# STM32U5A9xx register map
File version: 1.0
Registers are 32-bit, read-write, reset 0x0 unless marked. A register's access mark holds for its fields unless they carry their own. Offsets are from the block's base; [hi:lo] are bit positions; 'fields as' and 'values as' point back to an identical list.

## OCTOSPI1 — HEXA and OCTO Serial Peripheral Interface
Base 0x420D1400
Same registers: OCTOSPI2 0x420D2400, OCTOSPI1_S 0x520D1400, OCTOSPI2_S 0x520D2400
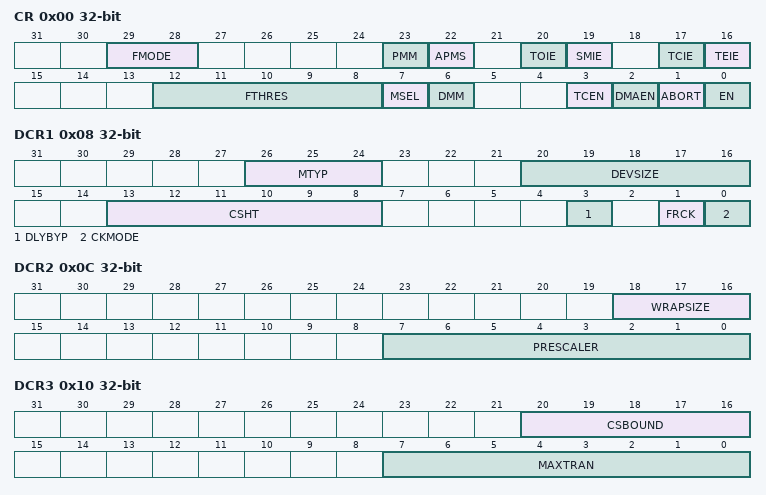
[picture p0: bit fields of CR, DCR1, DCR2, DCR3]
0x00 CR — XSPI Control register
  [29:28] FMODE — Functional Mode
  [23] PMM — Polling Match Mode
  [22] APMS — Automatic Poll Mode Stop
  [20] TOIE — TimeOut Interrupt Enable
  [19] SMIE — Status Match Interrupt Enable
  [17] TCIE — Transfer Complete Interrupt Enable
  [16] TEIE — Transfer Error Interrupt Enable
  [12:8] FTHRES — FIFO Threshold Level
  [7] MSEL — Memory Select
  [6] DMM — Dual Memory Mode
  [3] TCEN — Timeout Counter Enable
  [2] DMAEN — DMA Enable
  [1] ABORT — Abort request
  [0] EN — Enable
0x08 DCR1 — XSPI Device Configuration register 1
  [26:24] MTYP — Memory Type
  [20:16] DEVSIZE — Device Size
  [13:8] CSHT — Chip Select High Time
  [3] DLYBYP — Delay Block Bypass
  [1] FRCK — Free Running Clock
  [0] CKMODE — Mode 0 / Mode 3
0x0C DCR2 — XSPI Device Configuration register 2
  [18:16] WRAPSIZE
  [7:0] PRESCALER — Clock prescaler
0x10 DCR3 — XSPI Device Configuration register 3
  [20:16] CSBOUND — Maximum transfer
  [7:0] MAXTRAN — Maximum transfer
0x14 DCR4 — XSPI Device Configuration register 4
  [31:0] REFRESH — Refresh rate
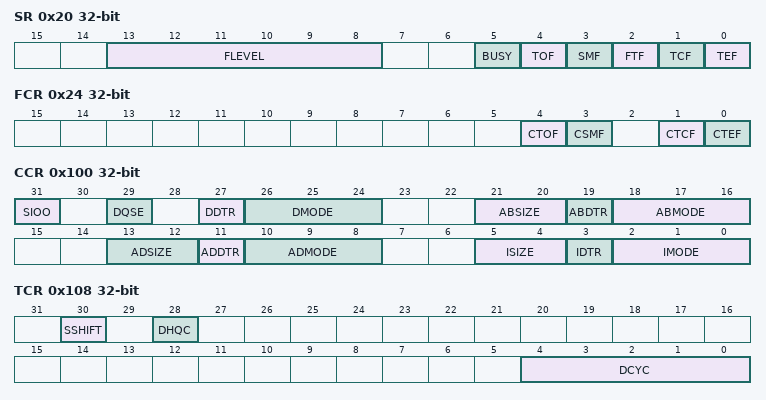
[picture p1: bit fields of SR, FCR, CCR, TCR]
0x20 SR — XSPI Status register
  [13:8] FLEVEL — FIFO Level
  [5] BUSY
  [4] TOF — Timeout Flag
  [3] SMF — Status Match Flag
  [2] FTF — FIFO Threshold Flag
  [1] TCF — Transfer Complete Flag
  [0] TEF — Transfer Error Flag
0x24 FCR — XSPI Flag Clear register
  [4] CTOF — Clear Timeout Flag
  [3] CSMF — Clear Status Match Flag
  [1] CTCF — Clear Transfer Complete Flag
  [0] CTEF — Clear Transfer Error Flag
0x40 DLR — XSPI Data Length register
  [31:0] DL — Data Length
0x48 AR — XSPI Address register
  [31:0] ADDRESS
0x50 DR — XSPI Data register
  [31:0] DATA
0x80 PSMKR — XSPI Polling Status Mask register
  [31:0] MASK — Status mask
0x88 PSMAR — XSPI Polling Status Match register
  [31:0] MATCH — Status match
0x90 PIR — XSPI Polling Interval register
  [15:0] INTERVAL — Polling Interval
0x100 CCR — XSPI Communication Configuration register
  [31] SIOO — Send Instruction Only Once Mode
  [29] DQSE — DQS Enable
  [27] DDTR — Data Double Transfer Rate
  [26:24] DMODE — Data Mode
  [21:20] ABSIZE — Alternate Bytes Size
  [19] ABDTR — Alternate Bytes Double Transfer Rate
  [18:16] ABMODE — Alternate Bytes Mode
  [13:12] ADSIZE — Address Size
  [11] ADDTR — Address Double Transfer Rate
  [10:8] ADMODE — Address Mode
  [5:4] ISIZE — Instruction Size
  [3] IDTR — Instruction Double Transfer Rate
  [2:0] IMODE — Instruction Mode
0x108 TCR — XSPI Timing Configuration register
  [30] SSHIFT — Sample Shift
  [28] DHQC — Delay Hold Quarter Cycle
  [4:0] DCYC — Number of Dummy Cycles
0x110 IR — XSPI Instruction register
  [31:0] INSTRUCTION
0x120 ABR — XSPI Alternate Bytes register
  [31:0] ALTERNATE — Alternate Bytes
0x130 LPTR — XSPI Low Power Timeout register
  [15:0] TIMEOUT — Timeout period
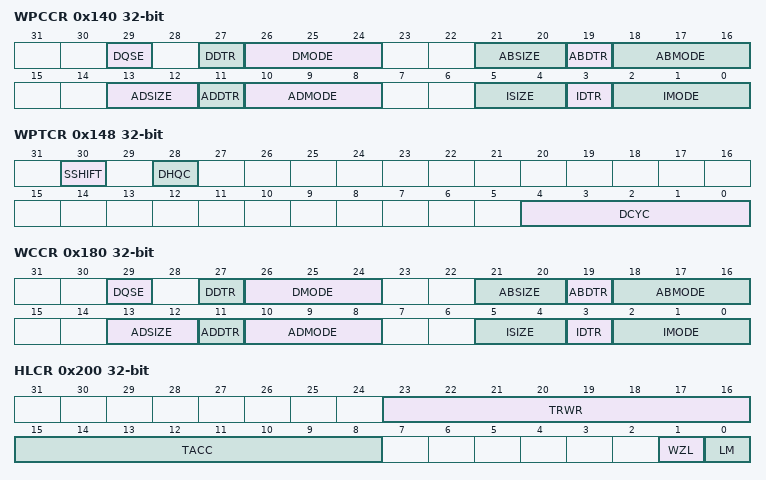
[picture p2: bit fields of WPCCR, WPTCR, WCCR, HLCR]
0x140 WPCCR — XSPI Wrap Communication Configuration register
  [29] DQSE — DQS Enable
  [27] DDTR — Data Double Transfer Rate
  [26:24] DMODE — Data Mode
  [21:20] ABSIZE — Alternate Bytes Size
  [19] ABDTR — Alternate Bytes Double Transfer Rate
  [18:16] ABMODE — Alternate Bytes Mode
  [13:12] ADSIZE — Address Size
  [11] ADDTR — Address Double Transfer Rate
  [10:8] ADMODE — Address Mode
  [5:4] ISIZE — Instruction Size
  [3] IDTR — Instruction Double Transfer Rate
  [2:0] IMODE — Instruction Mode
0x148 WPTCR — XSPI Wrap Timing Configuration register
  fields as TCR
0x150 WPIR — XSPI Wrap Instruction register
  [31:0] INSTRUCTION
0x160 WPABR — XSPI Wrap Alternate Bytes register
  [31:0] ALTERNATE — Alternate Bytes
0x180 WCCR — XSPI Write Communication Configuration register
  fields as WPCCR
0x188 WTCR — XSPI Write Timing Configuration register
  [4:0] DCYC — Number of Dummy Cycles
0x190 WIR — XSPI Write Instruction register
  [31:0] INSTRUCTION
0x1A0 WABR — XSPI Write Alternate Bytes register
  [31:0] ALTERNATE — Alternate Bytes
0x200 HLCR — XSPI Hyperbus Latency Configuration register
  [23:16] TRWR — Read Write Recovery Time
  [15:8] TACC — Access Time
  [1] WZL — Write Zero Latency
  [0] LM — Latency Mode
0x210 CALFCR — XSPI Full-cycle calibration configuration HSPI only, invalid for OCTOSPI
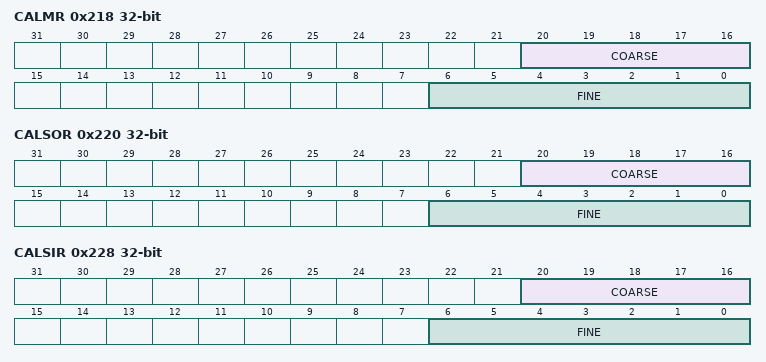
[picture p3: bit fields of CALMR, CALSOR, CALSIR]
0x218 CALMR — XSPI DLL master calibration configuration HSPI only, invalid for OCTOSPI
  [20:16] COARSE — Coarse Calibration
  [6:0] FINE — Fine Calibration
0x220 CALSOR — XSPI slave output calibration configuration HSPI only, invalid for OCTOSPI
  [20:16] COARSE — Coarse Calibration
  [6:0] FINE — Fine Calibration
0x228 CALSIR — XSPI slave input calibration configuration HSPI only, invalid for OCTOSPI
  [20:16] COARSE — Coarse Calibration
  [6:0] FINE — Fine Calibration

## HSPI1 — HEXA and OCTO Serial Peripheral Interface
Base 0x420D3400
Same registers: HSPI1_S 0x520D3400
Registers as OCTOSPI1; these are added or differ:
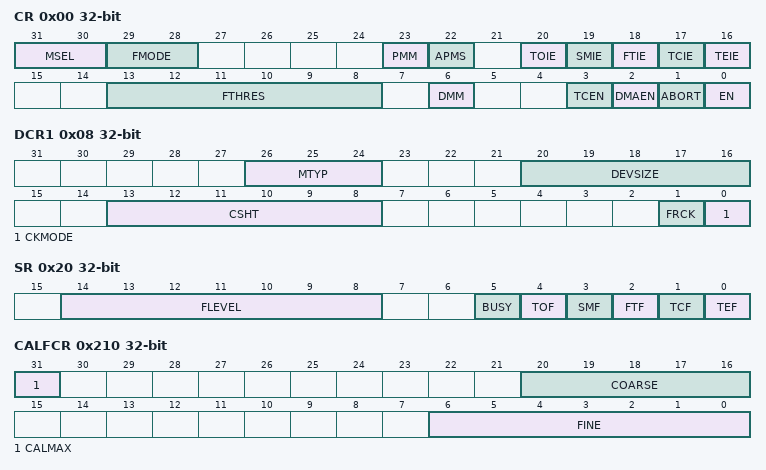
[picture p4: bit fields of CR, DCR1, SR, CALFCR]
0x00 CR — XSPI Control register
  [31:30] MSEL — Memory Select
  [29:28] FMODE — Functional Mode
  [23] PMM — Polling Match Mode
  [22] APMS — Automatic Poll Mode Stop
  [20] TOIE — TimeOut Interrupt Enable
  [19] SMIE — Status Match Interrupt Enable
  [18] FTIE — FIFO Threshold Interrupt Enable
  [17] TCIE — Transfer Complete Interrupt Enable
  [16] TEIE — Transfer Error Interrupt Enable
  [13:8] FTHRES — FIFO Threshold Level
  [6] DMM — Dual Memory Mode
  [3] TCEN — Timeout Counter Enable
  [2] DMAEN — DMA Enable
  [1] ABORT — Abort request
  [0] EN — Enable
0x08 DCR1 — XSPI Device Configuration register 1
  [26:24] MTYP — Memory Type
  [20:16] DEVSIZE — Device Size
  [13:8] CSHT — Chip Select High Time
  [1] FRCK — Free Running Clock
  [0] CKMODE — Mode 0 / Mode 3
0x10 DCR3 — XSPI Device Configuration register 3
  [20:16] CSBOUND — Maximum transfer
0x20 SR — XSPI Status register
  [14:8] FLEVEL — FIFO Level
  [5] BUSY
  [4] TOF — Timeout Flag
  [3] SMF — Status Match Flag
  [2] FTF — FIFO Threshold Flag
  [1] TCF — Transfer Complete Flag
  [0] TEF — Transfer Error Flag
0x210 CALFCR — XSPI Full-cycle calibration configuration HSPI only, invalid for OCTOSPI
  [31] CALMAX — Max Value
  [20:16] COARSE — Coarse Calibration
  [6:0] FINE — Fine Calibration
